AUTOSAR XML (schema 4-2-2)
package /STELLANTIS/EPT/ASWCs
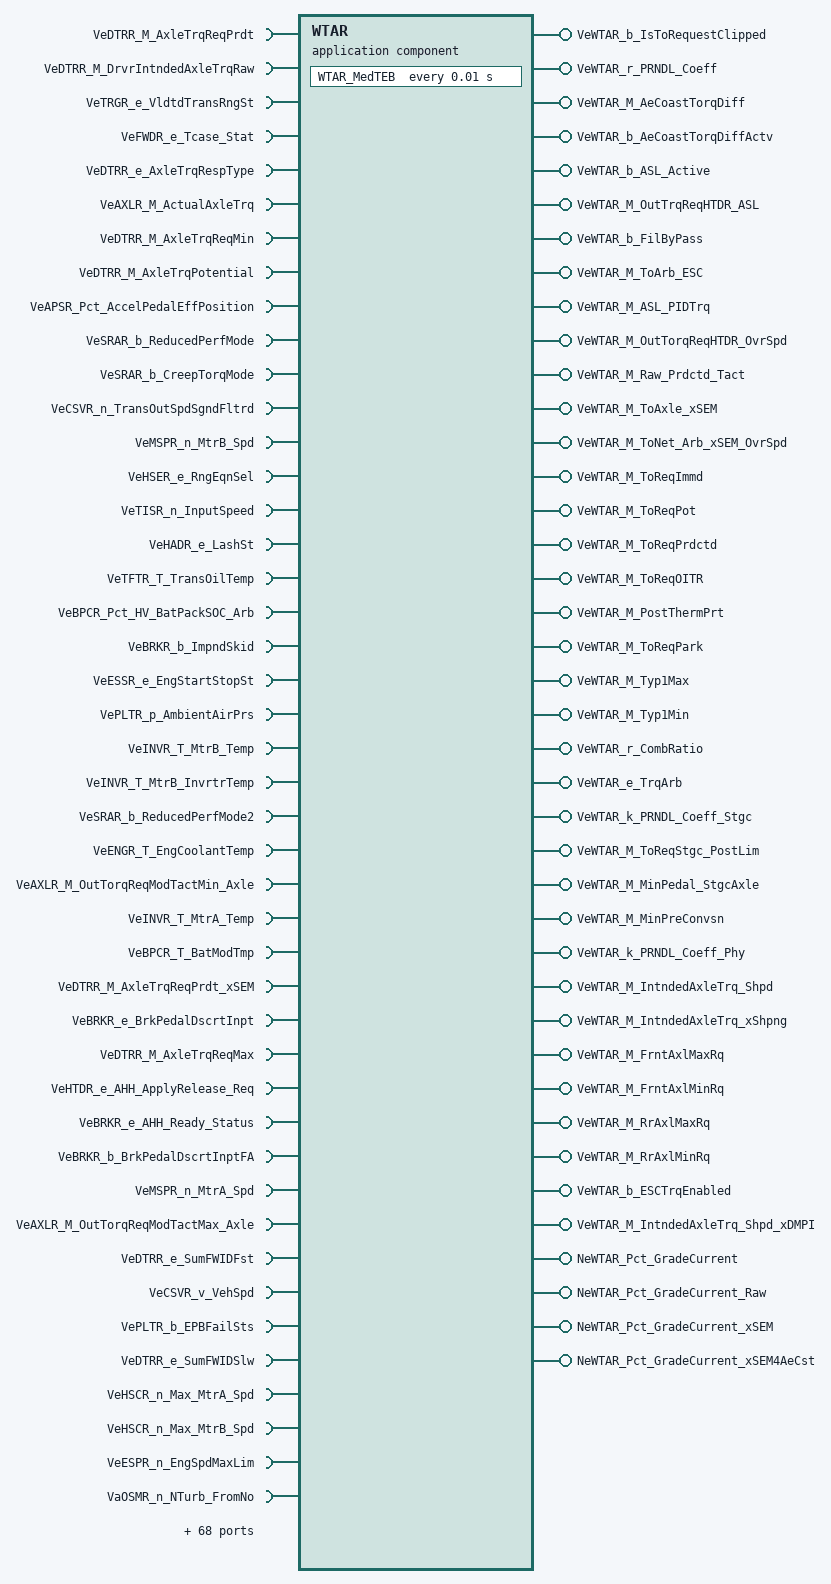
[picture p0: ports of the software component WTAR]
  application sw component type WTAR
    108 x require port:
      VeDTRR_M_AxleTrqReqPrdt: nonqueued-receiver-com-spec{data-element=Value, init-value=0}, required-interface=VeDTRR_M_AxleTrqReqPrdt
      VeDTRR_M_DrvrIntndedAxleTrqRaw: nonqueued-receiver-com-spec{data-element=Value, init-value=0}, required-interface=VeDTRR_M_DrvrIntndedAxleTrqRaw
      VeTRGR_e_VldtdTransRngSt: nonqueued-receiver-com-spec{data-element=Value, init-value=CeTRGR_e_NoSelectionAvailable}, required-interface=VeTRGR_e_VldtdTransRngSt
      VeFWDR_e_Tcase_Stat: nonqueued-receiver-com-spec{data-element=Value, init-value=CeFWDR_e_ShiftINProg}, required-interface=VeFWDR_e_Tcase_Stat
      VeDTRR_e_AxleTrqRespType: nonqueued-receiver-com-spec{data-element=Value, init-value=CePTAR_e_Inactive}, required-interface=VeDTRR_e_AxleTrqRespType
      VeAXLR_M_ActualAxleTrq: nonqueued-receiver-com-spec{data-element=Value, init-value=0}, required-interface=VeAXLR_M_ActualAxleTrq
      VeDTRR_M_AxleTrqReqMin: nonqueued-receiver-com-spec{data-element=Value, init-value=0}, required-interface=VeDTRR_M_AxleTrqReqMin
      VeDTRR_M_AxleTrqPotential: nonqueued-receiver-com-spec{data-element=Value, init-value=0}, required-interface=VeDTRR_M_AxleTrqPotential
      VeAPSR_Pct_AccelPedalEffPosition: nonqueued-receiver-com-spec{data-element=Value, init-value=0}, required-interface=VeAPSR_Pct_AccelPedalEffPosition
      VeSRAR_b_ReducedPerfMode: nonqueued-receiver-com-spec{data-element=Value, init-value=0}, required-interface=VeSRAR_b_ReducedPerfMode
      VeSRAR_b_CreepTorqMode: nonqueued-receiver-com-spec{data-element=Value, init-value=0}, required-interface=VeSRAR_b_CreepTorqMode
      VeCSVR_n_TransOutSpdSgndFltrd: nonqueued-receiver-com-spec{data-element=Value, init-value=0}, required-interface=VeCSVR_n_TransOutSpdSgndFltrd
      VeMSPR_n_MtrB_Spd: nonqueued-receiver-com-spec{data-element=Value, init-value=0}, required-interface=VeMSPR_n_MtrB_Spd
      VeHSER_e_RngEqnSel: nonqueued-receiver-com-spec{data-element=Value, init-value=CeHSER_e_UseNeutralEqn}, required-interface=VeHSER_e_RngEqnSel
      VeTISR_n_InputSpeed: nonqueued-receiver-com-spec{data-element=Value, init-value=0}, required-interface=VeTISR_n_InputSpeed
      VeHADR_e_LashSt: nonqueued-receiver-com-spec{data-element=Value, init-value=CeHADR_e_LashStZero}, required-interface=VeHADR_e_LashSt
      VeTFTR_T_TransOilTemp: nonqueued-receiver-com-spec{data-element=Value, init-value=0}, required-interface=VeTFTR_T_TransOilTemp
      VeBPCR_Pct_HV_BatPackSOC_Arb: nonqueued-receiver-com-spec{data-element=Value, init-value=0}, required-interface=VeBPCR_Pct_HV_BatPackSOC_Arb
      VeBRKR_b_ImpndSkid: nonqueued-receiver-com-spec{data-element=Value, init-value=0}, required-interface=VeBRKR_b_ImpndSkid
      VeESSR_e_EngStartStopSt: nonqueued-receiver-com-spec{data-element=Value, init-value=CeESSR_e_EngOff}, required-interface=VeESSR_e_EngStartStopSt
      VePLTR_p_AmbientAirPrs: nonqueued-receiver-com-spec{data-element=Value, init-value=0}, required-interface=VePLTR_p_AmbientAirPrs
      VeINVR_T_MtrB_Temp: nonqueued-receiver-com-spec{data-element=Value, init-value=0}, required-interface=VeINVR_T_MtrB_Temp
      VeINVR_T_MtrB_InvrtrTemp: nonqueued-receiver-com-spec{data-element=Value, init-value=0}, required-interface=VeINVR_T_MtrB_InvrtrTemp
      VeSRAR_b_ReducedPerfMode2: nonqueued-receiver-com-spec{data-element=Value, init-value=0}, required-interface=VeSRAR_b_ReducedPerfMode2
      VeENGR_T_EngCoolantTemp: nonqueued-receiver-com-spec{data-element=Value, init-value=0}, required-interface=VeENGR_T_EngCoolantTemp
      VeAXLR_M_OutTorqReqModTactMin_Axle: nonqueued-receiver-com-spec{data-element=Value, init-value=0}, required-interface=VeAXLR_M_OutTorqReqModTactMin_Axle
      VeINVR_T_MtrA_Temp: nonqueued-receiver-com-spec{data-element=Value, init-value=0}, required-interface=VeINVR_T_MtrA_Temp
      VeBPCR_T_BatModTmp: nonqueued-receiver-com-spec{data-element=Value, init-value=0}, required-interface=VeBPCR_T_BatModTmp
      VeDTRR_M_AxleTrqReqPrdt_xSEM: nonqueued-receiver-com-spec{data-element=Value, init-value=0}, required-interface=VeDTRR_M_AxleTrqReqPrdt_xSEM
      VeBRKR_e_BrkPedalDscrtInpt: nonqueued-receiver-com-spec{data-element=Value, init-value=CeBRKR_e_BrkNotApplied}, required-interface=VeBRKR_e_BrkPedalDscrtInpt
      VeDTRR_M_AxleTrqReqMax: nonqueued-receiver-com-spec{data-element=Value, init-value=0}, required-interface=VeDTRR_M_AxleTrqReqMax
      VeHTDR_e_AHH_ApplyRelease_Req: nonqueued-receiver-com-spec{data-element=Value, init-value=CeHTDR_e_AHH_Inactive}, required-interface=VeHTDR_e_AHH_ApplyRelease_Req
      VeBRKR_e_AHH_Ready_Status: nonqueued-receiver-com-spec{data-element=Value, init-value=CeBRKR_e_AHH_NotReady}, required-interface=VeBRKR_e_AHH_Ready_Status
      VeBRKR_b_BrkPedalDscrtInptFA: nonqueued-receiver-com-spec{data-element=Value, init-value=0}, required-interface=VeBRKR_b_BrkPedalDscrtInptFA
      VeMSPR_n_MtrA_Spd: nonqueued-receiver-com-spec{data-element=Value, init-value=0}, required-interface=VeMSPR_n_MtrA_Spd
      VeAXLR_M_OutTorqReqModTactMax_Axle: nonqueued-receiver-com-spec{data-element=Value, init-value=0}, required-interface=VeAXLR_M_OutTorqReqModTactMax_Axle
      VeDTRR_e_SumFWIDFst: nonqueued-receiver-com-spec{data-element=Value, init-value=CeDTRR_e_Potential}, required-interface=VeDTRR_e_SumFWIDFst
      VeCSVR_v_VehSpd: nonqueued-receiver-com-spec{data-element=Value, init-value=0}, required-interface=VeCSVR_v_VehSpd
      VePLTR_b_EPBFailSts: nonqueued-receiver-com-spec{data-element=Value, init-value=0}, required-interface=VePLTR_b_EPBFailSts
      VeDTRR_e_SumFWIDSlw: nonqueued-receiver-com-spec{data-element=Value, init-value=CeDTRR_e_Potential}, required-interface=VeDTRR_e_SumFWIDSlw
      VeHSCR_n_Max_MtrA_Spd: nonqueued-receiver-com-spec{data-element=Value, init-value=0}, required-interface=VeHSCR_n_Max_MtrA_Spd
      VeHSCR_n_Max_MtrB_Spd: nonqueued-receiver-com-spec{data-element=Value, init-value=0}, required-interface=VeHSCR_n_Max_MtrB_Spd
      VeESPR_n_EngSpdMaxLim: nonqueued-receiver-com-spec{data-element=Value, init-value=0}, required-interface=VeESPR_n_EngSpdMaxLim
      VaOSMR_n_NTurb_FromNo: nonqueued-receiver-com-spec{data-element=Value, init-value=9 x 0}, required-interface=VaOSMR_n_NTurb_FromNo
      VeVSDR_n_NTurb: nonqueued-receiver-com-spec{data-element=Value, init-value=0}, required-interface=VeVSDR_n_NTurb
      VeTRNR_n_NtiMaxATRR: nonqueued-receiver-com-spec{data-element=Value, init-value=0}, required-interface=VeTRNR_n_NtiMaxATRR
      VeTRNR_e_TargetGear: nonqueued-receiver-com-spec{data-element=Value, init-value=CeTRNR_e_Neutral}, required-interface=VeTRNR_e_TargetGear
      VeBTQR_r_TrqDmnConvSumToAxl: nonqueued-receiver-com-spec{data-element=Value, init-value=0}, required-interface=VeBTQR_r_TrqDmnConvSumToAxl
      VeCTCR_M_MinCreepWheelTrq: nonqueued-receiver-com-spec{data-element=Value, init-value=0}, required-interface=VeCTCR_M_MinCreepWheelTrq
      VeFWDR_r_TCaseRatio: nonqueued-receiver-com-spec{data-element=Value, init-value=0}, required-interface=VeFWDR_r_TCaseRatio
      VeFWDR_r_Axle_Ratio: nonqueued-receiver-com-spec{data-element=Value, init-value=0}, required-interface=VeFWDR_r_Axle_Ratio
      VeDTRR_M_NormalMinStgc: nonqueued-receiver-com-spec{data-element=Value, init-value=0}, required-interface=VeDTRR_M_NormalMinStgc
      VeAECR_b_AeCoastStat: nonqueued-receiver-com-spec{data-element=Value, init-value=0}, required-interface=VeAECR_b_AeCoastStat
      VeDTRR_b_Lv2RdPrfmActive: nonqueued-receiver-com-spec{data-element=Value, init-value=0}, required-interface=VeDTRR_b_Lv2RdPrfmActive
      VeAXLR_M_OutTorqReqModHH_Axle: nonqueued-receiver-com-spec{data-element=Value, init-value=0}, required-interface=VeAXLR_M_OutTorqReqModHH_Axle
      VeDTRR_M_DrvrIntndedAxleTrq: nonqueued-receiver-com-spec{data-element=Value, init-value=0}, required-interface=VeDTRR_M_DrvrIntndedAxleTrq
      VeDTRR_M_MgateMinTrq: nonqueued-receiver-com-spec{data-element=Value, init-value=0}, required-interface=VeDTRR_M_MgateMinTrq
      VeBRKR_b_OPDHoldStatusFA: nonqueued-receiver-com-spec{data-element=Value, init-value=0}, required-interface=VeBRKR_b_OPDHoldStatusFA
      VeBRKR_e_OPDHoldStatus: nonqueued-receiver-com-spec{data-element=Value, init-value=CeBRKR_e_In_Active}, required-interface=VeBRKR_e_OPDHoldStatus
      VeDTRR_b_OPD_Active: nonqueued-receiver-com-spec{data-element=Value, init-value=0}, required-interface=VeDTRR_b_OPD_Active
      VeTRGR_b_ManualMode: nonqueued-receiver-com-spec{data-element=Value, init-value=0}, required-interface=VeTRGR_b_ManualMode
      VeSCCR_M_FrntAxlMaxRq: nonqueued-receiver-com-spec{data-element=Value, init-value=0}, required-interface=VeSCCR_M_FrntAxlMaxRq
      VeSCCR_M_FrntAxlMinRq: nonqueued-receiver-com-spec{data-element=Value, init-value=0}, required-interface=VeSCCR_M_FrntAxlMinRq
      VeCCTR_b_CcEngaged: nonqueued-receiver-com-spec{data-element=Value, init-value=0}, required-interface=VeCCTR_b_CcEngaged
      VeTMDR_e_TrrnMd: variation-point={short-label=vpVeTMDR_e_TrrnMd, sw-syscond=1}, nonqueued-receiver-com-spec{data-element=Value, init-value=CeTMDR_e_NotDefine}, required-interface=VeTMDR_e_TrrnMd
      VeTRNR_e_ActualGear: nonqueued-receiver-com-spec{data-element=Value, init-value=CeTRNR_e_Neutral}, required-interface=VeTRNR_e_ActualGear
      VeTRNR_e_TCMActualEvenGear: nonqueued-receiver-com-spec{data-element=Value, init-value=CeTRNR_e_Neutral}, required-interface=VeTRNR_e_TCMActualEvenGear
      VeAXLR_M_MinTransTo_Axle: nonqueued-receiver-com-spec{data-element=Value, init-value=0}, required-interface=VeAXLR_M_MinTransTo_Axle
      VeASLR_M_PIDTrq: variation-point={short-label=vpVeASLR_M_PIDTrq, sw-syscond=1}, nonqueued-receiver-com-spec{data-element=Value, init-value=0}, required-interface=VeASLR_M_PIDTrq
      VeASLR_b_ASLActive: nonqueued-receiver-com-spec{data-element=Value, init-value=0}, required-interface=VeASLR_b_ASLActive
      VeCTCR_M_WheelTrqMinOverrev: nonqueued-receiver-com-spec{data-element=Value, init-value=0}, required-interface=VeCTCR_M_WheelTrqMinOverrev
      VeICSR_b_Disable_Ni_Global: nonqueued-receiver-com-spec{data-element=Value, init-value=0}, required-interface=VeICSR_b_Disable_Ni_Global
      VeBTQR_M_DrvrIntndedTotBrkTrq: nonqueued-receiver-com-spec{data-element=Value, init-value=0}, required-interface=VeBTQR_M_DrvrIntndedTotBrkTrq
      VeTINR_d_TCMLimphomeFaults: nonqueued-receiver-com-spec{data-element=Value, init-value=0}, required-interface=VeTINR_d_TCMLimphomeFaults
      VeAXLR_M_SumMaxTrqDsrd_Axle: nonqueued-receiver-com-spec{data-element=Value, init-value=0}, required-interface=VeAXLR_M_SumMaxTrqDsrd_Axle
      VeCSVR_a_VehAccel: nonqueued-receiver-com-spec{data-element=Value, init-value=0}, required-interface=VeCSVR_a_VehAccel
      VeATRR_b_SEM_Act: nonqueued-receiver-com-spec{data-element=Value, init-value=0}, required-interface=VeATRR_b_SEM_Act
      VeBTQR_b_DrvrIntndedTotBrkTrqFA: nonqueued-receiver-com-spec{data-element=Value, init-value=0}, required-interface=VeBTQR_b_DrvrIntndedTotBrkTrqFA
      VeCTCR_M_WheelMin4ECM: nonqueued-receiver-com-spec{data-element=Value, init-value=0}, required-interface=VeCTCR_M_WheelMin4ECM
      VeCTCR_M_TransIntakeWhlTgt_Raw: nonqueued-receiver-com-spec{data-element=Value, init-value=0}, required-interface=VeCTCR_M_TransIntakeWhlTgt_Raw
      VeCTCR_b_MinCreepWheelTrq_Enable: nonqueued-receiver-com-spec{data-element=Value, init-value=0}, required-interface=VeCTCR_b_MinCreepWheelTrq_Enable
      VeAXLR_M_OutTorqMaxArb_xSEM_Axle: nonqueued-receiver-com-spec{data-element=Value, init-value=0}, required-interface=VeAXLR_M_OutTorqMaxArb_xSEM_Axle
      VeINVR_T_MtrC_Temp: nonqueued-receiver-com-spec{data-element=Value, init-value=0}, required-interface=VeINVR_T_MtrC_Temp
      VeDTRR_e_RrAxleTrqRespType: nonqueued-receiver-com-spec{data-element=Value, init-value=CePTAR_e_Inactive}, required-interface=VeDTRR_e_RrAxleTrqRespType
      VePLTR_e_EPBHoldSts: nonqueued-receiver-com-spec{data-element=Value, init-value=CePLTR_e_EPBHoldSts_REL}, required-interface=VePLTR_e_EPBHoldSts
      VeDTRR_M_AxleTrqReqPrdt_xLv2RedPerf: nonqueued-receiver-com-spec{data-element=Value, init-value=0}, required-interface=VeDTRR_M_AxleTrqReqPrdt_xLv2RedPerf
      VeSCCR_M_RrAxlMaxRq: nonqueued-receiver-com-spec{data-element=Value, init-value=0}, required-interface=VeSCCR_M_RrAxlMaxRq
      VeSCCR_M_RrAxlMinRq: nonqueued-receiver-com-spec{data-element=Value, init-value=0}, required-interface=VeSCCR_M_RrAxlMinRq
      VeAXLR_M_ToMinArb_Axle: nonqueued-receiver-com-spec{data-element=Value, init-value=0}, required-interface=VeAXLR_M_ToMinArb_Axle
      VeAXLR_M_ToMaxArb_Axle: nonqueued-receiver-com-spec{data-element=Value, init-value=0}, required-interface=VeAXLR_M_ToMaxArb_Axle
      VeTMDR_i_TrueTrrnMd: variation-point={short-label=vpVeTMDR_i_TrueTrrnMd, sw-syscond=1}, nonqueued-receiver-com-spec{data-element=Value, init-value=0}, required-interface=VeTMDR_i_TrueTrrnMd
      VeDMDR_i_DrvMdArbIdx: variation-point={short-label=vpVeDMDR_i_DrvMdArbIdx, sw-syscond=1}, nonqueued-receiver-com-spec{data-element=Value, init-value=0}, required-interface=VeDMDR_i_DrvMdArbIdx
      VeTIMR_e_RaceOptions_Sts: nonqueued-receiver-com-spec{data-element=Value, init-value=CeTIMR_e_NoOptionSelected}, required-interface=VeTIMR_e_RaceOptions_Sts
      VeTIMR_e_RaceModeSts: nonqueued-receiver-com-spec{data-element=Value, init-value=CeTIMR_e_RaceMode_Off}, required-interface=VeTIMR_e_RaceModeSts
      VeTIMR_e_LaunchIntensity: nonqueued-receiver-com-spec{data-element=Value, init-value=CeTIMR_e_Max}, required-interface=VeTIMR_e_LaunchIntensity
      VeBRKR_b_BrkPdlFlt: nonqueued-receiver-com-spec{data-element=Value, init-value=0}, required-interface=VeBRKR_b_BrkPdlFlt
      VeBRKR_b_BrkPrssFA: nonqueued-receiver-com-spec{data-element=Value, init-value=0}, required-interface=VeBRKR_b_BrkPrssFA
      VeBPCR_T_HV_BatModTempAvg: nonqueued-receiver-com-spec{data-element=Value, init-value=0}, required-interface=VeBPCR_T_HV_BatModTempAvg
      VeAPSR_b_Lv1PvBrkActive: nonqueued-receiver-com-spec{data-element=Value, init-value=0}, required-interface=VeAPSR_b_Lv1PvBrkActive
      VePLTR_b_LwsAngleFA: nonqueued-receiver-com-spec{data-element=Value, init-value=0}, required-interface=VePLTR_b_LwsAngleFA
      VeSRAR_b_Inhibit_AWD_TerrainMode: nonqueued-receiver-com-spec{data-element=Value, init-value=0}, required-interface=VeSRAR_b_Inhibit_AWD_TerrainMode
      VeADCR_e_AWDSysStat: nonqueued-receiver-com-spec{data-element=Value, init-value=CeADCR_e_TwoWheelDrive}, required-interface=VeADCR_e_AWDSysStat
      VeBRKR_P_BrkPrss: nonqueued-receiver-com-spec{data-element=Value, init-value=0}, required-interface=VeBRKR_P_BrkPrss
      VePLTR_phi_LwsAngle: nonqueued-receiver-com-spec{data-element=Value, init-value=0}, required-interface=VePLTR_phi_LwsAngle
      VeAXLR_M_To_CL_Fast_Axle: nonqueued-receiver-com-spec{data-element=Value, init-value=0}, required-interface=VeAXLR_M_To_CL_Fast_Axle
      VeTTIR_dM_TCM_TrqGradLim_Lo_Axle: nonqueued-receiver-com-spec{data-element=Value, init-value=0}, required-interface=VeTTIR_dM_TCM_TrqGradLim_Lo_Axle
      VeTTIR_dM_TCM_TrqGradLim_Up_Axle: nonqueued-receiver-com-spec{data-element=Value, init-value=0}, required-interface=VeTTIR_dM_TCM_TrqGradLim_Up_Axle
      VeAPSR_e_Lv1PVMode: nonqueued-receiver-com-spec{data-element=Value, init-value=CeAPSR_e_LV1PVMode_NotValid}, required-interface=VeAPSR_e_Lv1PVMode
    36 x provide port:
      VeWTAR_b_IsToRequestClipped: nonqueued-sender-com-spec{data-element=Value, init-value=0}, provided-interface=VeWTAR_b_IsToRequestClipped
      VeWTAR_r_PRNDL_Coeff: nonqueued-sender-com-spec{data-element=Value, init-value=0}, provided-interface=VeWTAR_r_PRNDL_Coeff
      VeWTAR_M_AeCoastTorqDiff: nonqueued-sender-com-spec{data-element=Value, init-value=0}, provided-interface=VeWTAR_M_AeCoastTorqDiff
      VeWTAR_b_AeCoastTorqDiffActv: nonqueued-sender-com-spec{data-element=Value, init-value=0}, provided-interface=VeWTAR_b_AeCoastTorqDiffActv
      VeWTAR_b_ASL_Active: nonqueued-sender-com-spec{data-element=Value, init-value=0}, provided-interface=VeWTAR_b_ASL_Active
      VeWTAR_M_OutTrqReqHTDR_ASL: nonqueued-sender-com-spec{data-element=Value, init-value=0}, provided-interface=VeWTAR_M_OutTrqReqHTDR_ASL
      VeWTAR_b_FilByPass: nonqueued-sender-com-spec{data-element=Value, init-value=0}, provided-interface=VeWTAR_b_FilByPass
      VeWTAR_M_ToArb_ESC: nonqueued-sender-com-spec{data-element=Value, init-value=0}, provided-interface=VeWTAR_M_ToArb_ESC
      VeWTAR_M_ASL_PIDTrq: nonqueued-sender-com-spec{data-element=Value, init-value=0}, provided-interface=VeWTAR_M_ASL_PIDTrq
      VeWTAR_M_OutTorqReqHTDR_OvrSpd: nonqueued-sender-com-spec{data-element=Value, init-value=0}, provided-interface=VeWTAR_M_OutTorqReqHTDR_OvrSpd
      VeWTAR_M_Raw_Prdctd_Tact: nonqueued-sender-com-spec{data-element=Value, init-value=0}, provided-interface=VeWTAR_M_Raw_Prdctd_Tact
      VeWTAR_M_ToAxle_xSEM: nonqueued-sender-com-spec{data-element=Value, init-value=0}, provided-interface=VeWTAR_M_ToAxle_xSEM
      VeWTAR_M_ToNet_Arb_xSEM_OvrSpd: nonqueued-sender-com-spec{data-element=Value, init-value=0}, provided-interface=VeWTAR_M_ToNet_Arb_xSEM_OvrSpd
      VeWTAR_M_ToReqImmd: nonqueued-sender-com-spec{data-element=Value, init-value=0}, provided-interface=VeWTAR_M_ToReqImmd
      VeWTAR_M_ToReqPot: nonqueued-sender-com-spec{data-element=Value, init-value=0}, provided-interface=VeWTAR_M_ToReqPot
      VeWTAR_M_ToReqPrdctd: nonqueued-sender-com-spec{data-element=Value, init-value=0}, provided-interface=VeWTAR_M_ToReqPrdctd
      VeWTAR_M_ToReqOITR: nonqueued-sender-com-spec{data-element=Value, init-value=0}, provided-interface=VeWTAR_M_ToReqOITR
      VeWTAR_M_PostThermPrt: nonqueued-sender-com-spec{data-element=Value, init-value=0}, provided-interface=VeWTAR_M_PostThermPrt
      VeWTAR_M_ToReqPark: nonqueued-sender-com-spec{data-element=Value, init-value=0}, provided-interface=VeWTAR_M_ToReqPark
      VeWTAR_M_Typ1Max: nonqueued-sender-com-spec{data-element=Value, init-value=0}, provided-interface=VeWTAR_M_Typ1Max
      VeWTAR_M_Typ1Min: nonqueued-sender-com-spec{data-element=Value, init-value=0}, provided-interface=VeWTAR_M_Typ1Min
      VeWTAR_r_CombRatio: nonqueued-sender-com-spec{data-element=Value, init-value=0}, provided-interface=VeWTAR_r_CombRatio
      VeWTAR_e_TrqArb: nonqueued-sender-com-spec{data-element=Value, init-value=CeWTAR_e_ECM_TorqReqst}, provided-interface=VeWTAR_e_TrqArb
      VeWTAR_k_PRNDL_Coeff_Stgc: nonqueued-sender-com-spec{data-element=Value, init-value=0}, provided-interface=VeWTAR_k_PRNDL_Coeff_Stgc
      VeWTAR_M_ToReqStgc_PostLim: nonqueued-sender-com-spec{data-element=Value, init-value=0}, provided-interface=VeWTAR_M_ToReqStgc_PostLim
      VeWTAR_M_MinPedal_StgcAxle: nonqueued-sender-com-spec{data-element=Value, init-value=0}, provided-interface=VeWTAR_M_MinPedal_StgcAxle
      VeWTAR_M_MinPreConvsn: nonqueued-sender-com-spec{data-element=Value, init-value=0}, provided-interface=VeWTAR_M_MinPreConvsn
      VeWTAR_k_PRNDL_Coeff_Phy: nonqueued-sender-com-spec{data-element=Value, init-value=0}, provided-interface=VeWTAR_k_PRNDL_Coeff_Phy
      VeWTAR_M_IntndedAxleTrq_Shpd: nonqueued-sender-com-spec{data-element=Value, init-value=0}, provided-interface=VeWTAR_M_IntndedAxleTrq_Shpd
      VeWTAR_M_IntndedAxleTrq_xShpng: nonqueued-sender-com-spec{data-element=Value, init-value=0}, provided-interface=VeWTAR_M_IntndedAxleTrq_xShpng
      VeWTAR_M_FrntAxlMaxRq: nonqueued-sender-com-spec{data-element=Value, init-value=0}, provided-interface=VeWTAR_M_FrntAxlMaxRq
      VeWTAR_M_FrntAxlMinRq: nonqueued-sender-com-spec{data-element=Value, init-value=0}, provided-interface=VeWTAR_M_FrntAxlMinRq
      VeWTAR_M_RrAxlMaxRq: nonqueued-sender-com-spec{data-element=Value, init-value=0}, provided-interface=VeWTAR_M_RrAxlMaxRq
      VeWTAR_M_RrAxlMinRq: nonqueued-sender-com-spec{data-element=Value, init-value=0}, provided-interface=VeWTAR_M_RrAxlMinRq
      VeWTAR_b_ESCTrqEnabled: nonqueued-sender-com-spec{data-element=Value, init-value=0}, provided-interface=VeWTAR_b_ESCTrqEnabled
      VeWTAR_M_IntndedAxleTrq_Shpd_xDMPI: nonqueued-sender-com-spec{data-element=Value, init-value=0}, provided-interface=VeWTAR_M_IntndedAxleTrq_Shpd_xDMPI
    4 x require port:
      NeWTAR_Pct_GradeCurrent_Rx: nv-require-com-spec{init-value=0, variable=NeWTAR_Pct_GradeCurrent}, required-interface=NeWTAR_Pct_GradeCurrent
      NeWTAR_Pct_GradeCurrent_Raw_Rx: nv-require-com-spec{init-value=0, variable=NeWTAR_Pct_GradeCurrent_Raw}, required-interface=NeWTAR_Pct_GradeCurrent_Raw
      NeWTAR_Pct_GradeCurrent_xSEM_Rx: nv-require-com-spec{init-value=0, variable=NeWTAR_Pct_GradeCurrent_xSEM}, required-interface=NeWTAR_Pct_GradeCurrent_xSEM
      NeWTAR_Pct_GradeCurrent_xSEM4AeCst_Rx: nv-require-com-spec{init-value=0, variable=NeWTAR_Pct_GradeCurrent_xSEM4AeCst}, required-interface=NeWTAR_Pct_GradeCurrent_xSEM4AeCst
    4 x provide port:
      NeWTAR_Pct_GradeCurrent: nv-provide-com-spec{ram-block-init-value=0, variable=NeWTAR_Pct_GradeCurrent}, provided-interface=NeWTAR_Pct_GradeCurrent
      NeWTAR_Pct_GradeCurrent_Raw: nv-provide-com-spec{ram-block-init-value=0, variable=NeWTAR_Pct_GradeCurrent_Raw}, provided-interface=NeWTAR_Pct_GradeCurrent_Raw
      NeWTAR_Pct_GradeCurrent_xSEM: nv-provide-com-spec{ram-block-init-value=0, variable=NeWTAR_Pct_GradeCurrent_xSEM}, provided-interface=NeWTAR_Pct_GradeCurrent_xSEM
      NeWTAR_Pct_GradeCurrent_xSEM4AeCst: nv-provide-com-spec{ram-block-init-value=0, variable=NeWTAR_Pct_GradeCurrent_xSEM4AeCst}, provided-interface=NeWTAR_Pct_GradeCurrent_xSEM4AeCst
    behavior IB_WTAR: data-type-mapping=msADTtoIDTMapping, handle-termination-and-restart=NO-SUPPORT, included-data-type-set=data-type=TeWTAR_e_OvrSpdPtnTp
      timing event Event_MedTEB: start-on-event=WTAR_MedTEB, period=0.01
      init event Event_WTAR_ac_Init: start-on-event=WTAR_ac_Init
      init event Event_PwrOn: start-on-event=WTAR_PwrOn
      init event Event_PwrOff: start-on-event=WTAR_PwrOff
      4 x runnable:
        WTAR_ac_Init
          data-send-points:
            access OUT_VeWTAR_e_TrqArb_Value: accessed-variable=VeWTAR_e_TrqArb.Value
        WTAR_PwrOn
          data-receive-point-by-arguments:
            4 x access:
              IN_NeWTAR_Pct_GradeCurrent_Rx_NeWTAR_Pct_GradeCurrent: accessed-variable=NeWTAR_Pct_GradeCurrent_Rx.NeWTAR_Pct_GradeCurrent
              IN_NeWTAR_Pct_GradeCurrent_Raw_Rx_NeWTAR_Pct_GradeCurrent_Raw: accessed-variable=NeWTAR_Pct_GradeCurrent_Raw_Rx.NeWTAR_Pct_GradeCurrent_Raw
              IN_NeWTAR_Pct_GradeCurrent_xSEM4AeCst_Rx_NeWTAR_Pct_GradeCurrent_xSEM4AeCst: accessed-variable=NeWTAR_Pct_GradeCurrent_xSEM4AeCst_Rx.NeWTAR_Pct_GradeCurrent_xSEM4AeCst
              IN_NeWTAR_Pct_GradeCurrent_xSEM_Rx_NeWTAR_Pct_GradeCurrent_xSEM: accessed-variable=NeWTAR_Pct_GradeCurrent_xSEM_Rx.NeWTAR_Pct_GradeCurrent_xSEM
          data-send-points:
            36 x access:
              OUT_VeWTAR_e_TrqArb_Value: accessed-variable=VeWTAR_e_TrqArb.Value
              OUT_VeWTAR_b_IsToRequestClipped_Value: accessed-variable=VeWTAR_b_IsToRequestClipped.Value
              OUT_VeWTAR_r_PRNDL_Coeff_Value: accessed-variable=VeWTAR_r_PRNDL_Coeff.Value
              OUT_VeWTAR_M_AeCoastTorqDiff_Value: accessed-variable=VeWTAR_M_AeCoastTorqDiff.Value
              OUT_VeWTAR_b_AeCoastTorqDiffActv_Value: accessed-variable=VeWTAR_b_AeCoastTorqDiffActv.Value
              OUT_VeWTAR_b_ASL_Active_Value: accessed-variable=VeWTAR_b_ASL_Active.Value
              OUT_VeWTAR_M_OutTrqReqHTDR_ASL_Value: accessed-variable=VeWTAR_M_OutTrqReqHTDR_ASL.Value
              OUT_VeWTAR_b_FilByPass_Value: accessed-variable=VeWTAR_b_FilByPass.Value
              OUT_VeWTAR_M_ToArb_ESC_Value: accessed-variable=VeWTAR_M_ToArb_ESC.Value
              OUT_VeWTAR_M_ASL_PIDTrq_Value: accessed-variable=VeWTAR_M_ASL_PIDTrq.Value
              OUT_VeWTAR_M_OutTorqReqHTDR_OvrSpd_Value: accessed-variable=VeWTAR_M_OutTorqReqHTDR_OvrSpd.Value
              OUT_VeWTAR_M_Raw_Prdctd_Tact_Value: accessed-variable=VeWTAR_M_Raw_Prdctd_Tact.Value
              OUT_VeWTAR_M_ToAxle_xSEM_Value: accessed-variable=VeWTAR_M_ToAxle_xSEM.Value
              OUT_VeWTAR_M_ToNet_Arb_xSEM_OvrSpd_Value: accessed-variable=VeWTAR_M_ToNet_Arb_xSEM_OvrSpd.Value
              OUT_VeWTAR_M_ToReqImmd_Value: accessed-variable=VeWTAR_M_ToReqImmd.Value
              OUT_VeWTAR_M_ToReqPot_Value: accessed-variable=VeWTAR_M_ToReqPot.Value
              OUT_VeWTAR_M_ToReqPrdctd_Value: accessed-variable=VeWTAR_M_ToReqPrdctd.Value
              OUT_VeWTAR_M_ToReqOITR_Value: accessed-variable=VeWTAR_M_ToReqOITR.Value
              OUT_VeWTAR_M_PostThermPrt_Value: accessed-variable=VeWTAR_M_PostThermPrt.Value
              OUT_VeWTAR_M_ToReqPark_Value: accessed-variable=VeWTAR_M_ToReqPark.Value
              OUT_VeWTAR_M_Typ1Max_Value: accessed-variable=VeWTAR_M_Typ1Max.Value
              OUT_VeWTAR_M_Typ1Min_Value: accessed-variable=VeWTAR_M_Typ1Min.Value
              OUT_VeWTAR_r_CombRatio_Value: accessed-variable=VeWTAR_r_CombRatio.Value
              OUT_VeWTAR_k_PRNDL_Coeff_Stgc_Value: accessed-variable=VeWTAR_k_PRNDL_Coeff_Stgc.Value
              OUT_VeWTAR_M_ToReqStgc_PostLim_Value: accessed-variable=VeWTAR_M_ToReqStgc_PostLim.Value
              OUT_VeWTAR_M_MinPedal_StgcAxle_Value: accessed-variable=VeWTAR_M_MinPedal_StgcAxle.Value
              OUT_VeWTAR_M_MinPreConvsn_Value: accessed-variable=VeWTAR_M_MinPreConvsn.Value
              OUT_VeWTAR_k_PRNDL_Coeff_Phy_Value: accessed-variable=VeWTAR_k_PRNDL_Coeff_Phy.Value
              OUT_VeWTAR_M_IntndedAxleTrq_Shpd_Value: accessed-variable=VeWTAR_M_IntndedAxleTrq_Shpd.Value
              OUT_VeWTAR_M_IntndedAxleTrq_xShpng_Value: accessed-variable=VeWTAR_M_IntndedAxleTrq_xShpng.Value
              OUT_VeWTAR_M_FrntAxlMaxRq_Value: accessed-variable=VeWTAR_M_FrntAxlMaxRq.Value
              OUT_VeWTAR_M_FrntAxlMinRq_Value: accessed-variable=VeWTAR_M_FrntAxlMinRq.Value
              OUT_VeWTAR_M_RrAxlMinRq_Value: accessed-variable=VeWTAR_M_RrAxlMinRq.Value
              OUT_VeWTAR_M_RrAxlMaxRq_Value: accessed-variable=VeWTAR_M_RrAxlMaxRq.Value
              OUT_VeWTAR_b_ESCTrqEnabled_Value: accessed-variable=VeWTAR_b_ESCTrqEnabled.Value
              OUT_VeWTAR_M_IntndedAxleTrq_Shpd_xDMPI_Value: accessed-variable=VeWTAR_M_IntndedAxleTrq_Shpd_xDMPI.Value
        WTAR_MedTEB
          data-receive-point-by-arguments:
            107 x access:
              IN_VaOSMR_n_NTurb_FromNo_Value: accessed-variable=VaOSMR_n_NTurb_FromNo.Value
              IN_VeADCR_e_AWDSysStat_Value: accessed-variable=VeADCR_e_AWDSysStat.Value
              IN_VeAECR_b_AeCoastStat_Value: accessed-variable=VeAECR_b_AeCoastStat.Value
              IN_VeAPSR_Pct_AccelPedalEffPosition_Value: accessed-variable=VeAPSR_Pct_AccelPedalEffPosition.Value
              IN_VeAPSR_b_Lv1PvBrkActive_Value: accessed-variable=VeAPSR_b_Lv1PvBrkActive.Value
              IN_VeAPSR_e_Lv1PVMode_Value: accessed-variable=VeAPSR_e_Lv1PVMode.Value
              IN_VeASLR_M_PIDTrq_Value: accessed-variable=VeASLR_M_PIDTrq.Value, variation-point={short-label=vpIN_VeASLR_M_PIDTrq_Value, sw-syscond=1}
              IN_VeASLR_b_ASLActive_Value: accessed-variable=VeASLR_b_ASLActive.Value
              IN_VeATRR_b_SEM_Act_Value: accessed-variable=VeATRR_b_SEM_Act.Value
              IN_VeAXLR_M_ActualAxleTrq_Value: accessed-variable=VeAXLR_M_ActualAxleTrq.Value
              IN_VeAXLR_M_MinTransTo_Axle_Value: accessed-variable=VeAXLR_M_MinTransTo_Axle.Value
              IN_VeAXLR_M_OutTorqMaxArb_xSEM_Axle_Value: accessed-variable=VeAXLR_M_OutTorqMaxArb_xSEM_Axle.Value
              IN_VeAXLR_M_OutTorqReqModHH_Axle_Value: accessed-variable=VeAXLR_M_OutTorqReqModHH_Axle.Value
              IN_VeAXLR_M_OutTorqReqModTactMax_Axle_Value: accessed-variable=VeAXLR_M_OutTorqReqModTactMax_Axle.Value
              IN_VeAXLR_M_OutTorqReqModTactMin_Axle_Value: accessed-variable=VeAXLR_M_OutTorqReqModTactMin_Axle.Value
              IN_VeAXLR_M_SumMaxTrqDsrd_Axle_Value: accessed-variable=VeAXLR_M_SumMaxTrqDsrd_Axle.Value
              IN_VeAXLR_M_ToMaxArb_Axle_Value: accessed-variable=VeAXLR_M_ToMaxArb_Axle.Value
              IN_VeAXLR_M_ToMinArb_Axle_Value: accessed-variable=VeAXLR_M_ToMinArb_Axle.Value
              IN_VeAXLR_M_To_CL_Fast_Axle_Value: accessed-variable=VeAXLR_M_To_CL_Fast_Axle.Value
              IN_VeBPCR_Pct_HV_BatPackSOC_Arb_Value: accessed-variable=VeBPCR_Pct_HV_BatPackSOC_Arb.Value
              IN_VeBPCR_T_BatModTmp_Value: accessed-variable=VeBPCR_T_BatModTmp.Value
              IN_VeBPCR_T_HV_BatModTempAvg_Value: accessed-variable=VeBPCR_T_HV_BatModTempAvg.Value
              IN_VeBRKR_P_BrkPrss_Value: accessed-variable=VeBRKR_P_BrkPrss.Value
              IN_VeBRKR_b_BrkPdlFlt_Value: accessed-variable=VeBRKR_b_BrkPdlFlt.Value
              IN_VeBRKR_b_BrkPedalDscrtInptFA_Value: accessed-variable=VeBRKR_b_BrkPedalDscrtInptFA.Value
              IN_VeBRKR_b_BrkPrssFA_Value: accessed-variable=VeBRKR_b_BrkPrssFA.Value
              IN_VeBRKR_b_ImpndSkid_Value: accessed-variable=VeBRKR_b_ImpndSkid.Value
              IN_VeBRKR_b_OPDHoldStatusFA_Value: accessed-variable=VeBRKR_b_OPDHoldStatusFA.Value
              IN_VeBRKR_e_AHH_Ready_Status_Value: accessed-variable=VeBRKR_e_AHH_Ready_Status.Value
              IN_VeBRKR_e_BrkPedalDscrtInpt_Value: accessed-variable=VeBRKR_e_BrkPedalDscrtInpt.Value
              IN_VeBRKR_e_OPDHoldStatus_Value: accessed-variable=VeBRKR_e_OPDHoldStatus.Value
              IN_VeBTQR_M_DrvrIntndedTotBrkTrq_Value: accessed-variable=VeBTQR_M_DrvrIntndedTotBrkTrq.Value
              IN_VeBTQR_b_DrvrIntndedTotBrkTrqFA_Value: accessed-variable=VeBTQR_b_DrvrIntndedTotBrkTrqFA.Value
              IN_VeBTQR_r_TrqDmnConvSumToAxl_Value: accessed-variable=VeBTQR_r_TrqDmnConvSumToAxl.Value
              IN_VeCCTR_b_CcEngaged_Value: accessed-variable=VeCCTR_b_CcEngaged.Value
              IN_VeCSVR_a_VehAccel_Value: accessed-variable=VeCSVR_a_VehAccel.Value
              IN_VeCSVR_n_TransOutSpdSgndFltrd_Value: accessed-variable=VeCSVR_n_TransOutSpdSgndFltrd.Value
              IN_VeCSVR_v_VehSpd_Value: accessed-variable=VeCSVR_v_VehSpd.Value
              IN_VeCTCR_M_MinCreepWheelTrq_Value: accessed-variable=VeCTCR_M_MinCreepWheelTrq.Value
              IN_VeCTCR_M_TransIntakeWhlTgt_Raw_Value: accessed-variable=VeCTCR_M_TransIntakeWhlTgt_Raw.Value
              IN_VeCTCR_M_WheelMin4ECM_Value: accessed-variable=VeCTCR_M_WheelMin4ECM.Value
              IN_VeCTCR_M_WheelTrqMinOverrev_Value: accessed-variable=VeCTCR_M_WheelTrqMinOverrev.Value
              IN_VeCTCR_b_MinCreepWheelTrq_Enable_Value: accessed-variable=VeCTCR_b_MinCreepWheelTrq_Enable.Value
              IN_VeDMDR_i_DrvMdArbIdx_Value: accessed-variable=VeDMDR_i_DrvMdArbIdx.Value, variation-point={short-label=vpIN_VeDMDR_i_DrvMdArbIdx_Value, sw-syscond=1}
              IN_VeDTRR_M_AxleTrqPotential_Value: accessed-variable=VeDTRR_M_AxleTrqPotential.Value
              IN_VeDTRR_M_AxleTrqReqMax_Value: accessed-variable=VeDTRR_M_AxleTrqReqMax.Value
              IN_VeDTRR_M_AxleTrqReqMin_Value: accessed-variable=VeDTRR_M_AxleTrqReqMin.Value
              IN_VeDTRR_M_AxleTrqReqPrdt_Value: accessed-variable=VeDTRR_M_AxleTrqReqPrdt.Value
              IN_VeDTRR_M_AxleTrqReqPrdt_xLv2RedPerf_Value: accessed-variable=VeDTRR_M_AxleTrqReqPrdt_xLv2RedPerf.Value
              IN_VeDTRR_M_AxleTrqReqPrdt_xSEM_Value: accessed-variable=VeDTRR_M_AxleTrqReqPrdt_xSEM.Value
              IN_VeDTRR_M_DrvrIntndedAxleTrq_Value: accessed-variable=VeDTRR_M_DrvrIntndedAxleTrq.Value
              IN_VeDTRR_M_DrvrIntndedAxleTrqRaw_Value: accessed-variable=VeDTRR_M_DrvrIntndedAxleTrqRaw.Value
              IN_VeDTRR_M_MgateMinTrq_Value: accessed-variable=VeDTRR_M_MgateMinTrq.Value
              IN_VeDTRR_M_NormalMinStgc_Value: accessed-variable=VeDTRR_M_NormalMinStgc.Value
              IN_VeDTRR_b_Lv2RdPrfmActive_Value: accessed-variable=VeDTRR_b_Lv2RdPrfmActive.Value
              IN_VeDTRR_b_OPD_Active_Value: accessed-variable=VeDTRR_b_OPD_Active.Value
              IN_VeDTRR_e_AxleTrqRespType_Value: accessed-variable=VeDTRR_e_AxleTrqRespType.Value
              IN_VeDTRR_e_RrAxleTrqRespType_Value: accessed-variable=VeDTRR_e_RrAxleTrqRespType.Value
              IN_VeDTRR_e_SumFWIDFst_Value: accessed-variable=VeDTRR_e_SumFWIDFst.Value
              IN_VeDTRR_e_SumFWIDSlw_Value: accessed-variable=VeDTRR_e_SumFWIDSlw.Value
              IN_VeENGR_T_EngCoolantTemp_Value: accessed-variable=VeENGR_T_EngCoolantTemp.Value
              IN_VeESPR_n_EngSpdMaxLim_Value: accessed-variable=VeESPR_n_EngSpdMaxLim.Value
              IN_VeESSR_e_EngStartStopSt_Value: accessed-variable=VeESSR_e_EngStartStopSt.Value
              IN_VeFWDR_e_Tcase_Stat_Value: accessed-variable=VeFWDR_e_Tcase_Stat.Value
              IN_VeFWDR_r_Axle_Ratio_Value: accessed-variable=VeFWDR_r_Axle_Ratio.Value
              IN_VeFWDR_r_TCaseRatio_Value: accessed-variable=VeFWDR_r_TCaseRatio.Value
              IN_VeHADR_e_LashSt_Value: accessed-variable=VeHADR_e_LashSt.Value
              IN_VeHSCR_n_Max_MtrA_Spd_Value: accessed-variable=VeHSCR_n_Max_MtrA_Spd.Value
              IN_VeHSCR_n_Max_MtrB_Spd_Value: accessed-variable=VeHSCR_n_Max_MtrB_Spd.Value
              IN_VeHSER_e_RngEqnSel_Value: accessed-variable=VeHSER_e_RngEqnSel.Value
              IN_VeHTDR_e_AHH_ApplyRelease_Req_Value: accessed-variable=VeHTDR_e_AHH_ApplyRelease_Req.Value
              IN_VeICSR_b_Disable_Ni_Global_Value: accessed-variable=VeICSR_b_Disable_Ni_Global.Value
              IN_VeINVR_T_MtrA_Temp_Value: accessed-variable=VeINVR_T_MtrA_Temp.Value
              IN_VeINVR_T_MtrB_InvrtrTemp_Value: accessed-variable=VeINVR_T_MtrB_InvrtrTemp.Value
              IN_VeINVR_T_MtrB_Temp_Value: accessed-variable=VeINVR_T_MtrB_Temp.Value
              IN_VeINVR_T_MtrC_Temp_Value: accessed-variable=VeINVR_T_MtrC_Temp.Value
              IN_VeMSPR_n_MtrA_Spd_Value: accessed-variable=VeMSPR_n_MtrA_Spd.Value
              IN_VeMSPR_n_MtrB_Spd_Value: accessed-variable=VeMSPR_n_MtrB_Spd.Value
              IN_VePLTR_b_LwsAngleFA_Value: accessed-variable=VePLTR_b_LwsAngleFA.Value
              IN_VePLTR_e_EPBHoldSts_Value: accessed-variable=VePLTR_e_EPBHoldSts.Value
              IN_VePLTR_p_AmbientAirPrs_Value: accessed-variable=VePLTR_p_AmbientAirPrs.Value
              IN_VePLTR_phi_LwsAngle_Value: accessed-variable=VePLTR_phi_LwsAngle.Value
              IN_VeSCCR_M_FrntAxlMaxRq_Value: accessed-variable=VeSCCR_M_FrntAxlMaxRq.Value
              IN_VeSCCR_M_FrntAxlMinRq_Value: accessed-variable=VeSCCR_M_FrntAxlMinRq.Value
              IN_VeSCCR_M_RrAxlMaxRq_Value: accessed-variable=VeSCCR_M_RrAxlMaxRq.Value
              IN_VeSCCR_M_RrAxlMinRq_Value: accessed-variable=VeSCCR_M_RrAxlMinRq.Value
              IN_VeSRAR_b_CreepTorqMode_Value: accessed-variable=VeSRAR_b_CreepTorqMode.Value
              IN_VeSRAR_b_Inhibit_AWD_TerrainMode_Value: accessed-variable=VeSRAR_b_Inhibit_AWD_TerrainMode.Value
              IN_VeSRAR_b_ReducedPerfMode_Value: accessed-variable=VeSRAR_b_ReducedPerfMode.Value
              IN_VeSRAR_b_ReducedPerfMode2_Value: accessed-variable=VeSRAR_b_ReducedPerfMode2.Value
              IN_VeTFTR_T_TransOilTemp_Value: accessed-variable=VeTFTR_T_TransOilTemp.Value
              IN_VeTIMR_e_LaunchIntensity_Value: accessed-variable=VeTIMR_e_LaunchIntensity.Value
              IN_VeTIMR_e_RaceModeSts_Value: accessed-variable=VeTIMR_e_RaceModeSts.Value
              IN_VeTIMR_e_RaceOptions_Sts_Value: accessed-variable=VeTIMR_e_RaceOptions_Sts.Value
              IN_VeTINR_d_TCMLimphomeFaults_Value: accessed-variable=VeTINR_d_TCMLimphomeFaults.Value
              IN_VeTISR_n_InputSpeed_Value: accessed-variable=VeTISR_n_InputSpeed.Value
              IN_VeTMDR_e_TrrnMd_Value: accessed-variable=VeTMDR_e_TrrnMd.Value, variation-point={short-label=vpIN_VeTMDR_e_TrrnMd_Value, sw-syscond=1}
              IN_VeTMDR_i_TrueTrrnMd_Value: accessed-variable=VeTMDR_i_TrueTrrnMd.Value, variation-point={short-label=vpIN_VeTMDR_i_TrueTrrnMd_Value, sw-syscond=1}
              IN_VeTRGR_b_ManualMode_Value: accessed-variable=VeTRGR_b_ManualMode.Value
              IN_VeTRGR_e_VldtdTransRngSt_Value: accessed-variable=VeTRGR_e_VldtdTransRngSt.Value
              IN_VeTRNR_e_ActualGear_Value: accessed-variable=VeTRNR_e_ActualGear.Value
              IN_VeTRNR_e_TCMActualEvenGear_Value: accessed-variable=VeTRNR_e_TCMActualEvenGear.Value
              IN_VeTRNR_e_TargetGear_Value: accessed-variable=VeTRNR_e_TargetGear.Value
              IN_VeTRNR_n_NtiMaxATRR_Value: accessed-variable=VeTRNR_n_NtiMaxATRR.Value
              IN_VeTTIR_dM_TCM_TrqGradLim_Lo_Axle_Value: accessed-variable=VeTTIR_dM_TCM_TrqGradLim_Lo_Axle.Value
              IN_VeTTIR_dM_TCM_TrqGradLim_Up_Axle_Value: accessed-variable=VeTTIR_dM_TCM_TrqGradLim_Up_Axle.Value
              IN_VeVSDR_n_NTurb_Value: accessed-variable=VeVSDR_n_NTurb.Value
          data-send-points:
            36 x access:
              OUT_VeWTAR_M_Typ1Max_Value: accessed-variable=VeWTAR_M_Typ1Max.Value
              OUT_VeWTAR_M_Typ1Min_Value: accessed-variable=VeWTAR_M_Typ1Min.Value
              OUT_VeWTAR_k_PRNDL_Coeff_Stgc_Value: accessed-variable=VeWTAR_k_PRNDL_Coeff_Stgc.Value
              OUT_VeWTAR_M_MinPedal_StgcAxle_Value: accessed-variable=VeWTAR_M_MinPedal_StgcAxle.Value
              OUT_VeWTAR_M_MinPreConvsn_Value: accessed-variable=VeWTAR_M_MinPreConvsn.Value
              OUT_VeWTAR_k_PRNDL_Coeff_Phy_Value: accessed-variable=VeWTAR_k_PRNDL_Coeff_Phy.Value
              OUT_VeWTAR_e_TrqArb_Value: accessed-variable=VeWTAR_e_TrqArb.Value
              OUT_VeWTAR_M_ToArb_ESC_Value: accessed-variable=VeWTAR_M_ToArb_ESC.Value
              OUT_VeWTAR_M_PostThermPrt_Value: accessed-variable=VeWTAR_M_PostThermPrt.Value
              OUT_VeWTAR_b_IsToRequestClipped_Value: accessed-variable=VeWTAR_b_IsToRequestClipped.Value
              OUT_VeWTAR_M_AeCoastTorqDiff_Value: accessed-variable=VeWTAR_M_AeCoastTorqDiff.Value
              OUT_VeWTAR_b_AeCoastTorqDiffActv_Value: accessed-variable=VeWTAR_b_AeCoastTorqDiffActv.Value
              OUT_VeWTAR_b_ASL_Active_Value: accessed-variable=VeWTAR_b_ASL_Active.Value
              OUT_VeWTAR_M_OutTrqReqHTDR_ASL_Value: accessed-variable=VeWTAR_M_OutTrqReqHTDR_ASL.Value
              OUT_VeWTAR_b_FilByPass_Value: accessed-variable=VeWTAR_b_FilByPass.Value
              OUT_VeWTAR_M_ASL_PIDTrq_Value: accessed-variable=VeWTAR_M_ASL_PIDTrq.Value
              OUT_VeWTAR_M_OutTorqReqHTDR_OvrSpd_Value: accessed-variable=VeWTAR_M_OutTorqReqHTDR_OvrSpd.Value
              OUT_VeWTAR_M_Raw_Prdctd_Tact_Value: accessed-variable=VeWTAR_M_Raw_Prdctd_Tact.Value
              OUT_VeWTAR_M_ToAxle_xSEM_Value: accessed-variable=VeWTAR_M_ToAxle_xSEM.Value
              OUT_VeWTAR_M_ToNet_Arb_xSEM_OvrSpd_Value: accessed-variable=VeWTAR_M_ToNet_Arb_xSEM_OvrSpd.Value
              OUT_VeWTAR_M_ToReqImmd_Value: accessed-variable=VeWTAR_M_ToReqImmd.Value
              OUT_VeWTAR_M_ToReqPot_Value: accessed-variable=VeWTAR_M_ToReqPot.Value
              OUT_VeWTAR_M_ToReqPrdctd_Value: accessed-variable=VeWTAR_M_ToReqPrdctd.Value
              OUT_VeWTAR_M_ToReqOITR_Value: accessed-variable=VeWTAR_M_ToReqOITR.Value
              OUT_VeWTAR_M_ToReqPark_Value: accessed-variable=VeWTAR_M_ToReqPark.Value
              OUT_VeWTAR_r_CombRatio_Value: accessed-variable=VeWTAR_r_CombRatio.Value
              OUT_VeWTAR_M_ToReqStgc_PostLim_Value: accessed-variable=VeWTAR_M_ToReqStgc_PostLim.Value
              OUT_VeWTAR_M_IntndedAxleTrq_Shpd_Value: accessed-variable=VeWTAR_M_IntndedAxleTrq_Shpd.Value
              OUT_VeWTAR_M_IntndedAxleTrq_xShpng_Value: accessed-variable=VeWTAR_M_IntndedAxleTrq_xShpng.Value
              OUT_VeWTAR_r_PRNDL_Coeff_Value: accessed-variable=VeWTAR_r_PRNDL_Coeff.Value
              OUT_VeWTAR_M_FrntAxlMaxRq_Value: accessed-variable=VeWTAR_M_FrntAxlMaxRq.Value
              OUT_VeWTAR_M_FrntAxlMinRq_Value: accessed-variable=VeWTAR_M_FrntAxlMinRq.Value
              OUT_VeWTAR_M_RrAxlMaxRq_Value: accessed-variable=VeWTAR_M_RrAxlMaxRq.Value
              OUT_VeWTAR_M_RrAxlMinRq_Value: accessed-variable=VeWTAR_M_RrAxlMinRq.Value
              OUT_VeWTAR_b_ESCTrqEnabled_Value: accessed-variable=VeWTAR_b_ESCTrqEnabled.Value
              OUT_VeWTAR_M_IntndedAxleTrq_Shpd_xDMPI_Value: accessed-variable=VeWTAR_M_IntndedAxleTrq_Shpd_xDMPI.Value
        WTAR_PwrOff
          data-send-points:
            4 x access:
              OUT_NeWTAR_Pct_GradeCurrent_NeWTAR_Pct_GradeCurrent: accessed-variable=NeWTAR_Pct_GradeCurrent.NeWTAR_Pct_GradeCurrent
              OUT_NeWTAR_Pct_GradeCurrent_Raw_NeWTAR_Pct_GradeCurrent_Raw: accessed-variable=NeWTAR_Pct_GradeCurrent_Raw.NeWTAR_Pct_GradeCurrent_Raw
              OUT_NeWTAR_Pct_GradeCurrent_xSEM_NeWTAR_Pct_GradeCurrent_xSEM: accessed-variable=NeWTAR_Pct_GradeCurrent_xSEM.NeWTAR_Pct_GradeCurrent_xSEM
              OUT_NeWTAR_Pct_GradeCurrent_xSEM4AeCst_NeWTAR_Pct_GradeCurrent_xSEM4AeCst: accessed-variable=NeWTAR_Pct_GradeCurrent_xSEM4AeCst.NeWTAR_Pct_GradeCurrent_xSEM4AeCst
      10 x variation point proxy, all with category=CONDITION:
        Variant_WTAR_1: condition-access=0
        Variant_WTAR_10: condition-access=1
        Variant_WTAR_{2..7}: condition-access=0
        Variant_WTAR_8: condition-access=1
        Variant_WTAR_9: condition-access=0
